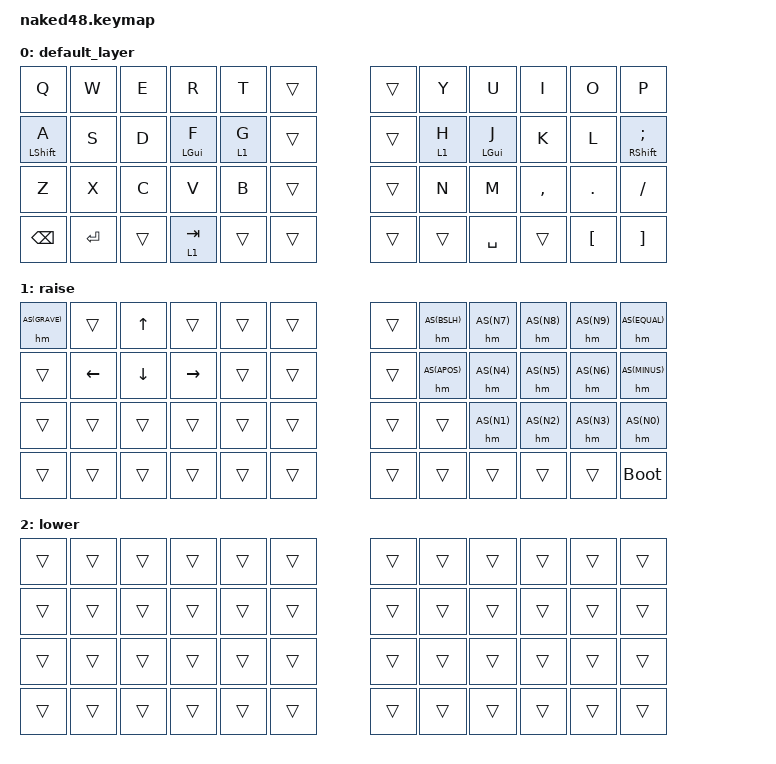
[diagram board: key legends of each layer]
/*
 * Copyright (c) 2020 The ZMK Contributors
 *
 * SPDX-License-Identifier: MIT
 */

#include <behaviors.dtsi>
#include <dt-bindings/zmk/keys.h>
#include <dt-bindings/zmk/bt.h>
#include <dt-bindings/zmk/outputs.h>
#include <dt-bindings/zmk/rgb.h>


#include <dt-bindings/led/led.h>

&spi1 {
   compatible = "nordic,nrf-spim";
   status = "okay";
   mosi-pin = <6>;
   // Unused pins, needed for SPI definition, but not used by the ws2812 driver itself.
   sck-pin = <5>;
   miso-pin = <7>;

   led_strip: ws2812@0 {
      compatible = "worldsemi,ws2812-spi";
      label = "WS2812";

      /* SPI */
      reg = <0>; /* ignored, but necessary for SPI bindings */
      spi-max-frequency = <4000000>;

      /* WS2812 */
      chain-length = <48>; /* arbitrary; change at will */
      spi-one-frame = <0x70>;
      spi-zero-frame = <0x40>;
      color-mapping = <
         LED_COLOR_ID_GREEN
         LED_COLOR_ID_RED
         LED_COLOR_ID_BLUE
      >;
   };
};

/ {
   chosen {
      zmk,underglow = &led_strip;
   };
};

#define AS(keycode) LS(keycode) keycode

/ {
    behaviors {
        hm: homerow_mods {
            compatible = "zmk,behavior-hold-tap";
            label = "HOMEROW_MODS";
            #binding-cells = <2>;
            tapping-term-ms = <150>;
            quick-tap-ms = <0>;
            flavor = "tap-preferred";
            bindings = <&kp>, <&kp>;
        };
        hl: homerow_layers {
            compatible = "zmk,behavior-hold-tap";
            label = "HOMEROW_LAYERS";
            #binding-cells = <2>;
            tapping-term-ms = <120>;
            quick-tap-ms = <0>;
            flavor = "tap-preferred";
            bindings = <&mo>, <&kp>;
        };
    };

    keymap {
        compatible = "zmk,keymap";

        default_layer {
            bindings = <
                &kp Q           &kp W       &kp E           &kp R           &kp T       &trans                              &trans          &kp Y       &kp U          &kp I           &kp O           &kp P
                &hm LSHIFT A    &kp S       &kp D           &hm LGUI F      &hl 1 G     &trans                              &trans          &hl 1 H     &hm LGUI J     &kp K           &kp L           &hm RSHIFT SEMI
                &kp Z           &kp X       &kp C           &kp V           &kp B       &trans                              &trans          &kp N       &kp M          &kp COMMA       &kp DOT         &kp FSLH
                                &kp BSPC    &kp RET         &trans          &hl 1 TAB   &trans       &trans      &trans     &trans          &kp SPACE   &trans         &kp LBKT        &kp RBKT
            >;
        };

        raise {
            bindings = <
                &hm AS(GRAVE)   &trans      &kp UP          &trans          &trans      &trans                              &trans          &hm AS(BSLH) &hm AS(N7)     &hm AS(N8)      &hm AS(N9)      &hm AS(EQUAL)
                &trans          &kp LEFT    &kp DOWN        &kp RIGHT       &trans      &trans                              &trans          &hm AS(APOS) &hm AS(N4)     &hm AS(N5)      &hm AS(N6)      &hm AS(MINUS)
                &trans          &trans      &trans          &trans          &trans      &trans                              &trans          &trans       &hm AS(N1)     &hm AS(N2)      &hm AS(N3)      &hm AS(N0)
                                &trans      &trans          &trans          &trans      &trans      &trans      &trans      &trans          &trans       &trans         &trans          &bootloader
            >;
        };

        lower {
            bindings = <
                &trans          &trans      &trans          &trans          &trans      &trans                              &trans          &trans      &trans         &trans          &trans         &trans
                &trans          &trans      &trans          &trans          &trans      &trans                              &trans          &trans      &trans         &trans          &trans         &trans
                &trans          &trans      &trans          &trans          &trans      &trans                              &trans          &trans      &trans         &trans          &trans         &trans
                                &trans      &trans          &trans          &trans      &trans      &trans      &trans      &trans          &trans      &trans         &trans          &trans
            >;
        };
    };
};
